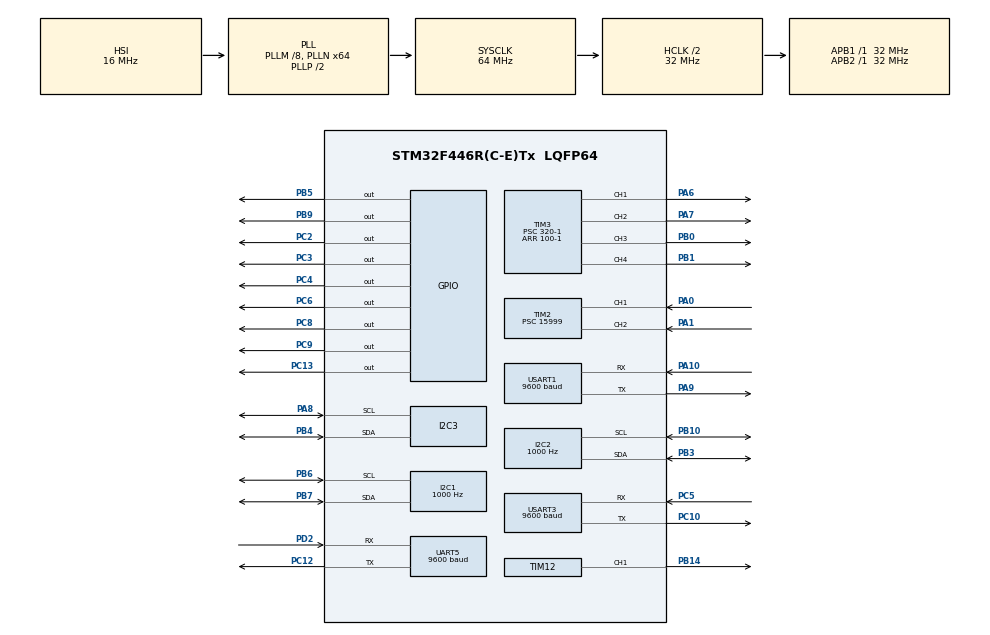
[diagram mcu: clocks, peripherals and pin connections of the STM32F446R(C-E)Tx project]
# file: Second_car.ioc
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I2C1.ClockSpeed=1000
I2C2.ClockSpeed=1000
I2C2.OwnAddress=60
Mcu.Family=STM32F4
Mcu.Name=STM32F446R(C-E)Tx
Mcu.Package=LQFP64
NVIC.PriorityGroup=NVIC_PRIORITYGROUP_4
NVIC.TIM2_IRQn=true\:0\:0\:true\:false\:true\:true\:true\:true
NVIC.TIM7_IRQn=true\:15\:0\:false\:false\:true\:false\:true\:true
NVIC.TimeBase=TIM7_IRQn
NVIC.TimeBaseIP=TIM7
NVIC.UART5_IRQn=true\:0\:0\:false\:false\:true\:true\:true\:true
NVIC.USART1_IRQn=true\:6\:0\:true\:false\:true\:true\:true\:true
NVIC.USART3_IRQn=true\:1\:0\:true\:false\:true\:true\:true\:true
PA0-WKUP.Signal=S_TIM2_CH1_ETR
PA1.Signal=S_TIM2_CH2
PA10.Mode=Asynchronous
PA10.Signal=USART1_RX
PA6.Signal=S_TIM3_CH1
PA7.Signal=S_TIM3_CH2
PA8.Mode=I2C
PA8.Signal=I2C3_SCL
PA9.Mode=Asynchronous
PA9.Signal=USART1_TX
PB0.Signal=S_TIM3_CH3
PB1.Signal=S_TIM3_CH4
PB10.Mode=I2C
PB10.Signal=I2C2_SCL
PB14.Signal=S_TIM12_CH1
PB3.Mode=I2C
PB3.Signal=I2C2_SDA
PB4.Mode=I2C
PB4.Signal=I2C3_SDA
PB5.Signal=GPIO_Output
PB6.Mode=I2C
PB6.Signal=I2C1_SCL
PB7.Mode=I2C
PB7.Signal=I2C1_SDA
PB9.Signal=GPIO_Output
PC10.Mode=Asynchronous
PC10.Signal=USART3_TX
PC12.Mode=Asynchronous
PC12.Signal=UART5_TX
PC13.Signal=GPIO_Output
PC2.Signal=GPIO_Output
PC3.Signal=GPIO_Output
PC4.Signal=GPIO_Output
PC5.Mode=Asynchronous
PC5.Signal=USART3_RX
PC6.Signal=GPIO_Output
PC8.Signal=GPIO_Output
PC9.Signal=GPIO_Output
PD2.Mode=Asynchronous
PD2.Signal=UART5_RX
ProjectManager.HeapSize=0x200
ProjectManager.StackSize=0x400
ProjectManager.TargetToolchain=STM32CubeIDE
RCC.AHBCLKDivider=RCC_SYSCLK_DIV2
RCC.AHBFreq_Value=32000000
RCC.APB1Freq_Value=32000000
RCC.APB1TimFreq_Value=32000000
RCC.APB2Freq_Value=32000000
RCC.APB2TimFreq_Value=32000000
RCC.CortexFreq_Value=32000000
RCC.HCLKFreq_Value=32000000
RCC.PLLM=8
RCC.PLLN=64
RCC.SYSCLKFreq_VALUE=64000000
RCC.SYSCLKSource=RCC_SYSCLKSOURCE_PLLCLK
RCC.USBFreq_Value=64000000
RCC.VCOOutputFreq_Value=128000000
SH.S_TIM12_CH1.0=TIM12_CH1,PWM Generation1 CH1
SH.S_TIM2_CH1_ETR.0=TIM2_CH1,Input_Capture1_from_TI1
SH.S_TIM2_CH2.0=TIM2_CH2,Input_Capture2_from_TI2
SH.S_TIM3_CH1.0=TIM3_CH1,PWM Generation1 CH1
SH.S_TIM3_CH2.0=TIM3_CH2,PWM Generation2 CH2
SH.S_TIM3_CH3.0=TIM3_CH3,PWM Generation3 CH3
SH.S_TIM3_CH4.0=TIM3_CH4,PWM Generation4 CH4
TIM12.Channel-PWM\ Generation1\ CH1=TIM_CHANNEL_1
TIM12.Period=100-1
TIM12.Prescaler=160-1
TIM2.Channel-Input_Capture1_from_TI1=TIM_CHANNEL_1
TIM2.Channel-Input_Capture2_from_TI2=TIM_CHANNEL_2
TIM2.ICPolarity_CH1=TIM_INPUTCHANNELPOLARITY_BOTHEDGE
TIM2.Period=12000
TIM2.Prescaler=15999
TIM3.Channel-PWM\ Generation1\ CH1=TIM_CHANNEL_1
TIM3.Channel-PWM\ Generation2\ CH2=TIM_CHANNEL_2
TIM3.Channel-PWM\ Generation3\ CH3=TIM_CHANNEL_3
TIM3.Channel-PWM\ Generation4\ CH4=TIM_CHANNEL_4
TIM3.Period=100-1
TIM3.Prescaler=320-1
UART5.BaudRate=9600
UART5.VirtualMode=Asynchronous
USART1.BaudRate=9600
USART1.VirtualMode=VM_ASYNC
USART3.BaudRate=9600
USART3.VirtualMode=VM_ASYNC
VP_SYS_VS_tim7.Mode=TIM7
VP_TIM6_VS_ClockSourceINT.Mode=Enable_Timer
board=custom

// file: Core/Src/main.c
/* USER CODE BEGIN Header */
/**
  ******************************************************************************
  * @file           : main.c
  * @brief          : Main program body
  ******************************************************************************
  * @attention
  *
  * Copyright (c) 2024 STMicroelectronics.
  * All rights reserved.
  *
  * This software is licensed under terms that can be found in the LICENSE file
  * in the root directory of this software component.
  * If no LICENSE file comes with this software, it is provided AS-IS.
  *
  ******************************************************************************
  */
/* USER CODE END Header */
#include "main.h"

/* USER CODE BEGIN Includes */
#include "calculateSpeed.h"
/* USER CODE END Includes */

I2C_HandleTypeDef hi2c1;
I2C_HandleTypeDef hi2c2;
I2C_HandleTypeDef hi2c3;

TIM_HandleTypeDef htim2;
TIM_HandleTypeDef htim3;
TIM_HandleTypeDef htim6;
TIM_HandleTypeDef htim12;

UART_HandleTypeDef huart5;
UART_HandleTypeDef huart1;
UART_HandleTypeDef huart3;

void SystemClock_Config(void);
static void MX_GPIO_Init(void);
static void MX_I2C1_Init(void);
static void MX_USART1_UART_Init(void);
static void MX_USART3_UART_Init(void);
static void MX_TIM2_Init(void);
static void MX_I2C2_Init(void);
static void MX_I2C3_Init(void);
static void MX_TIM3_Init(void);
static void MX_UART5_Init(void);
static void MX_TIM6_Init(void);
static void MX_TIM12_Init(void);

/* USER CODE BEGIN 0 */
uint8_t is_two_readings = 0;
uint32_t edges_counter = 0;
uint16_t Global_Speed;
/* USER CODE END 0 */

int main(void)
{
  /* USER CODE BEGIN 1 */

//	recieveBluetooth(&charRecieved);
  /* USER CODE END 1 */

  /* MCU Configuration--------------------------------------------------------*/

  /* Reset of all peripherals, Initializes the Flash interface and the Systick. */
  HAL_Init();

  /* Configure the system clock */
  SystemClock_Config();

  /* Initialize all configured peripherals */
  MX_GPIO_Init();
  MX_I2C1_Init();
  MX_USART1_UART_Init();
  MX_USART3_UART_Init();
  MX_TIM2_Init();
  MX_I2C2_Init();
  MX_I2C3_Init();
  MX_TIM3_Init();
  MX_UART5_Init();
  MX_TIM6_Init();
  MX_TIM12_Init();

  /* Infinite loop */
  /* USER CODE BEGIN WHILE */
  while (1)
  {
//	 recieveBluetooth(&charRecieved);
    /* USER CODE END WHILE */

  }
}

void SystemClock_Config(void)
{
  RCC_OscInitTypeDef RCC_OscInitStruct = {0};
  RCC_ClkInitTypeDef RCC_ClkInitStruct = {0};

  /** Configure the main internal regulator output voltage
  */
  __HAL_RCC_PWR_CLK_ENABLE();
  __HAL_PWR_VOLTAGESCALING_CONFIG(PWR_REGULATOR_VOLTAGE_SCALE3);

  /** Initializes the RCC Oscillators according to the specified parameters
  * in the RCC_OscInitTypeDef structure.
  */
  RCC_OscInitStruct.OscillatorType = RCC_OSCILLATORTYPE_HSI;
  RCC_OscInitStruct.HSIState = RCC_HSI_ON;
  RCC_OscInitStruct.HSICalibrationValue = RCC_HSICALIBRATION_DEFAULT;
  RCC_OscInitStruct.PLL.PLLState = RCC_PLL_ON;
  RCC_OscInitStruct.PLL.PLLSource = RCC_PLLSOURCE_HSI;
  RCC_OscInitStruct.PLL.PLLM = 8;
  RCC_OscInitStruct.PLL.PLLN = 64;
  RCC_OscInitStruct.PLL.PLLP = RCC_PLLP_DIV2;
  RCC_OscInitStruct.PLL.PLLQ = 2;
  RCC_OscInitStruct.PLL.PLLR = 2;
  if (HAL_RCC_OscConfig(&RCC_OscInitStruct) != HAL_OK)
  {
    Error_Handler();
  }

  /** Initializes the CPU, AHB and APB buses clocks
  */
  RCC_ClkInitStruct.ClockType = RCC_CLOCKTYPE_HCLK|RCC_CLOCKTYPE_SYSCLK
                              |RCC_CLOCKTYPE_PCLK1|RCC_CLOCKTYPE_PCLK2;
  RCC_ClkInitStruct.SYSCLKSource = RCC_SYSCLKSOURCE_PLLCLK;
  RCC_ClkInitStruct.AHBCLKDivider = RCC_SYSCLK_DIV2;
  RCC_ClkInitStruct.APB1CLKDivider = RCC_HCLK_DIV1;
  RCC_ClkInitStruct.APB2CLKDivider = RCC_HCLK_DIV1;

  if (HAL_RCC_ClockConfig(&RCC_ClkInitStruct, FLASH_LATENCY_1) != HAL_OK)
  {
    Error_Handler();
  }
}

static void MX_I2C1_Init(void)
{

  hi2c1.Instance = I2C1;
  hi2c1.Init.ClockSpeed = 1000;
  hi2c1.Init.DutyCycle = I2C_DUTYCYCLE_2;
  hi2c1.Init.OwnAddress1 = 0;
  hi2c1.Init.AddressingMode = I2C_ADDRESSINGMODE_7BIT;
  hi2c1.Init.DualAddressMode = I2C_DUALADDRESS_DISABLE;
  hi2c1.Init.OwnAddress2 = 0;
  hi2c1.Init.GeneralCallMode = I2C_GENERALCALL_DISABLE;
  hi2c1.Init.NoStretchMode = I2C_NOSTRETCH_DISABLE;
  if (HAL_I2C_Init(&hi2c1) != HAL_OK)
  {
    Error_Handler();
  }

}

static void MX_I2C2_Init(void)
{

  hi2c2.Instance = I2C2;
  hi2c2.Init.ClockSpeed = 1000;
  hi2c2.Init.DutyCycle = I2C_DUTYCYCLE_2;
  hi2c2.Init.OwnAddress1 = 120;
  hi2c2.Init.AddressingMode = I2C_ADDRESSINGMODE_7BIT;
  hi2c2.Init.DualAddressMode = I2C_DUALADDRESS_DISABLE;
  hi2c2.Init.OwnAddress2 = 0;
  hi2c2.Init.GeneralCallMode = I2C_GENERALCALL_DISABLE;
  hi2c2.Init.NoStretchMode = I2C_NOSTRETCH_DISABLE;
  if (HAL_I2C_Init(&hi2c2) != HAL_OK)
  {
    Error_Handler();
  }

}

static void MX_I2C3_Init(void)
{

  hi2c3.Instance = I2C3;
  hi2c3.Init.ClockSpeed = 100000;
  hi2c3.Init.DutyCycle = I2C_DUTYCYCLE_2;
  hi2c3.Init.OwnAddress1 = 0;
  hi2c3.Init.AddressingMode = I2C_ADDRESSINGMODE_7BIT;
  hi2c3.Init.DualAddressMode = I2C_DUALADDRESS_DISABLE;
  hi2c3.Init.OwnAddress2 = 0;
  hi2c3.Init.GeneralCallMode = I2C_GENERALCALL_DISABLE;
  hi2c3.Init.NoStretchMode = I2C_NOSTRETCH_DISABLE;
  if (HAL_I2C_Init(&hi2c3) != HAL_OK)
  {
    Error_Handler();
  }

}

static void MX_TIM2_Init(void)
{

  TIM_MasterConfigTypeDef sMasterConfig = {0};
  TIM_IC_InitTypeDef sConfigIC = {0};

  htim2.Instance = TIM2;
  htim2.Init.Prescaler = 15999;
  htim2.Init.CounterMode = TIM_COUNTERMODE_UP;
  htim2.Init.Period = 12000;
  htim2.Init.ClockDivision = TIM_CLOCKDIVISION_DIV1;
  htim2.Init.AutoReloadPreload = TIM_AUTORELOAD_PRELOAD_DISABLE;
  if (HAL_TIM_IC_Init(&htim2) != HAL_OK)
  {
    Error_Handler();
  }
  sMasterConfig.MasterOutputTrigger = TIM_TRGO_RESET;
  sMasterConfig.MasterSlaveMode = TIM_MASTERSLAVEMODE_DISABLE;
  if (HAL_TIMEx_MasterConfigSynchronization(&htim2, &sMasterConfig) != HAL_OK)
  {
    Error_Handler();
  }
  sConfigIC.ICPolarity = TIM_INPUTCHANNELPOLARITY_BOTHEDGE;
  sConfigIC.ICSelection = TIM_ICSELECTION_DIRECTTI;
  sConfigIC.ICPrescaler = TIM_ICPSC_DIV1;
  sConfigIC.ICFilter = 0;
  if (HAL_TIM_IC_ConfigChannel(&htim2, &sConfigIC, TIM_CHANNEL_1) != HAL_OK)
  {
    Error_Handler();
  }
  sConfigIC.ICPolarity = TIM_INPUTCHANNELPOLARITY_RISING;
  if (HAL_TIM_IC_ConfigChannel(&htim2, &sConfigIC, TIM_CHANNEL_2) != HAL_OK)
  {
    Error_Handler();
  }

}

static void MX_TIM3_Init(void)
{

  TIM_MasterConfigTypeDef sMasterConfig = {0};
  TIM_OC_InitTypeDef sConfigOC = {0};

  htim3.Instance = TIM3;
  htim3.Init.Prescaler = 320-1;
  htim3.Init.CounterMode = TIM_COUNTERMODE_UP;
  htim3.Init.Period = 100-1;
  htim3.Init.ClockDivision = TIM_CLOCKDIVISION_DIV1;
  htim3.Init.AutoReloadPreload = TIM_AUTORELOAD_PRELOAD_DISABLE;
  if (HAL_TIM_PWM_Init(&htim3) != HAL_OK)
  {
    Error_Handler();
  }
  sMasterConfig.MasterOutputTrigger = TIM_TRGO_RESET;
  sMasterConfig.MasterSlaveMode = TIM_MASTERSLAVEMODE_DISABLE;
  if (HAL_TIMEx_MasterConfigSynchronization(&htim3, &sMasterConfig) != HAL_OK)
  {
    Error_Handler();
  }
  sConfigOC.OCMode = TIM_OCMODE_PWM1;
  sConfigOC.Pulse = 0;
  sConfigOC.OCPolarity = TIM_OCPOLARITY_HIGH;
  sConfigOC.OCFastMode = TIM_OCFAST_DISABLE;
  if (HAL_TIM_PWM_ConfigChannel(&htim3, &sConfigOC, TIM_CHANNEL_1) != HAL_OK)
  {
    Error_Handler();
  }
  if (HAL_TIM_PWM_ConfigChannel(&htim3, &sConfigOC, TIM_CHANNEL_2) != HAL_OK)
  {
    Error_Handler();
  }
  if (HAL_TIM_PWM_ConfigChannel(&htim3, &sConfigOC, TIM_CHANNEL_3) != HAL_OK)
  {
    Error_Handler();
  }
  if (HAL_TIM_PWM_ConfigChannel(&htim3, &sConfigOC, TIM_CHANNEL_4) != HAL_OK)
  {
    Error_Handler();
  }
  HAL_TIM_MspPostInit(&htim3);

}

static void MX_TIM6_Init(void)
{

  TIM_MasterConfigTypeDef sMasterConfig = {0};

  htim6.Instance = TIM6;
  htim6.Init.Prescaler = 0;
  htim6.Init.CounterMode = TIM_COUNTERMODE_UP;
  htim6.Init.Period = 65535;
  htim6.Init.AutoReloadPreload = TIM_AUTORELOAD_PRELOAD_DISABLE;
  if (HAL_TIM_Base_Init(&htim6) != HAL_OK)
  {
    Error_Handler();
  }
  sMasterConfig.MasterOutputTrigger = TIM_TRGO_RESET;
  sMasterConfig.MasterSlaveMode = TIM_MASTERSLAVEMODE_DISABLE;
  if (HAL_TIMEx_MasterConfigSynchronization(&htim6, &sMasterConfig) != HAL_OK)
  {
    Error_Handler();
  }

}

static void MX_TIM12_Init(void)
{

  TIM_OC_InitTypeDef sConfigOC = {0};

  htim12.Instance = TIM12;
  htim12.Init.Prescaler = 160-1;
  htim12.Init.CounterMode = TIM_COUNTERMODE_UP;
  htim12.Init.Period = 100-1;
  htim12.Init.ClockDivision = TIM_CLOCKDIVISION_DIV1;
  htim12.Init.AutoReloadPreload = TIM_AUTORELOAD_PRELOAD_DISABLE;
  if (HAL_TIM_PWM_Init(&htim12) != HAL_OK)
  {
    Error_Handler();
  }
  sConfigOC.OCMode = TIM_OCMODE_PWM1;
  sConfigOC.Pulse = 0;
  sConfigOC.OCPolarity = TIM_OCPOLARITY_HIGH;
  sConfigOC.OCFastMode = TIM_OCFAST_DISABLE;
  if (HAL_TIM_PWM_ConfigChannel(&htim12, &sConfigOC, TIM_CHANNEL_1) != HAL_OK)
  {
    Error_Handler();
  }
  HAL_TIM_MspPostInit(&htim12);

}

static void MX_UART5_Init(void)
{

  huart5.Instance = UART5;
  huart5.Init.BaudRate = 9600;
  huart5.Init.WordLength = UART_WORDLENGTH_8B;
  huart5.Init.StopBits = UART_STOPBITS_1;
  huart5.Init.Parity = UART_PARITY_NONE;
  huart5.Init.Mode = UART_MODE_TX_RX;
  huart5.Init.HwFlowCtl = UART_HWCONTROL_NONE;
  huart5.Init.OverSampling = UART_OVERSAMPLING_16;
  if (HAL_UART_Init(&huart5) != HAL_OK)
  {
    Error_Handler();
  }

}

static void MX_USART1_UART_Init(void)
{

  huart1.Instance = USART1;
  huart1.Init.BaudRate = 9600;
  huart1.Init.WordLength = UART_WORDLENGTH_8B;
  huart1.Init.StopBits = UART_STOPBITS_1;
  huart1.Init.Parity = UART_PARITY_NONE;
  huart1.Init.Mode = UART_MODE_TX_RX;
  huart1.Init.HwFlowCtl = UART_HWCONTROL_NONE;
  huart1.Init.OverSampling = UART_OVERSAMPLING_16;
  if (HAL_UART_Init(&huart1) != HAL_OK)
  {
    Error_Handler();
  }

}

static void MX_USART3_UART_Init(void)
{

  huart3.Instance = USART3;
  huart3.Init.BaudRate = 9600;
  huart3.Init.WordLength = UART_WORDLENGTH_8B;
  huart3.Init.StopBits = UART_STOPBITS_1;
  huart3.Init.Parity = UART_PARITY_NONE;
  huart3.Init.Mode = UART_MODE_TX_RX;
  huart3.Init.HwFlowCtl = UART_HWCONTROL_NONE;
  huart3.Init.OverSampling = UART_OVERSAMPLING_16;
  if (HAL_UART_Init(&huart3) != HAL_OK)
  {
    Error_Handler();
  }

}

static void MX_GPIO_Init(void)
{
  GPIO_InitTypeDef GPIO_InitStruct = {0};

  /* GPIO Ports Clock Enable */
  __HAL_RCC_GPIOC_CLK_ENABLE();
  __HAL_RCC_GPIOA_CLK_ENABLE();
  __HAL_RCC_GPIOB_CLK_ENABLE();
  __HAL_RCC_GPIOD_CLK_ENABLE();

  /*Configure GPIO pin Output Level */
  HAL_GPIO_WritePin(GPIOC, GPIO_PIN_13|GPIO_PIN_2|GPIO_PIN_3|GPIO_PIN_4
                          |GPIO_PIN_6|GPIO_PIN_8|GPIO_PIN_9, GPIO_PIN_RESET);

  /*Configure GPIO pin Output Level */
  HAL_GPIO_WritePin(GPIOB, GPIO_PIN_5|GPIO_PIN_9, GPIO_PIN_RESET);

  /*Configure GPIO pins : PC13 PC2 PC3 PC4
                           PC6 PC8 PC9 */
  GPIO_InitStruct.Pin = GPIO_PIN_13|GPIO_PIN_2|GPIO_PIN_3|GPIO_PIN_4
                          |GPIO_PIN_6|GPIO_PIN_8|GPIO_PIN_9;
  GPIO_InitStruct.Mode = GPIO_MODE_OUTPUT_PP;
  GPIO_InitStruct.Pull = GPIO_NOPULL;
  GPIO_InitStruct.Speed = GPIO_SPEED_FREQ_LOW;
  HAL_GPIO_Init(GPIOC, &GPIO_InitStruct);

  /*Configure GPIO pins : PB5 PB9 */
  GPIO_InitStruct.Pin = GPIO_PIN_5|GPIO_PIN_9;
  GPIO_InitStruct.Mode = GPIO_MODE_OUTPUT_PP;
  GPIO_InitStruct.Pull = GPIO_NOPULL;
  GPIO_InitStruct.Speed = GPIO_SPEED_FREQ_LOW;
  HAL_GPIO_Init(GPIOB, &GPIO_InitStruct);

}

/* USER CODE BEGIN 4 */
void HAL_TIM_IC_CaptureCallback(TIM_HandleTypeDef *htim)
{
  if (htim->Instance == TIM2 && (htim->Channel == HAL_TIM_ACTIVE_CHANNEL_1 || htim->Channel == HAL_TIM_ACTIVE_CHANNEL_2))
  {
	  edges_counter++;
  }
}
/* USER CODE END 4 */

void HAL_TIM_PeriodElapsedCallback(TIM_HandleTypeDef *htim)
{
  if (htim->Instance == TIM7) {
    HAL_IncTick();
  }
}

void Error_Handler(void)
{
  __disable_irq();
  while (1)
  {
  }
}
